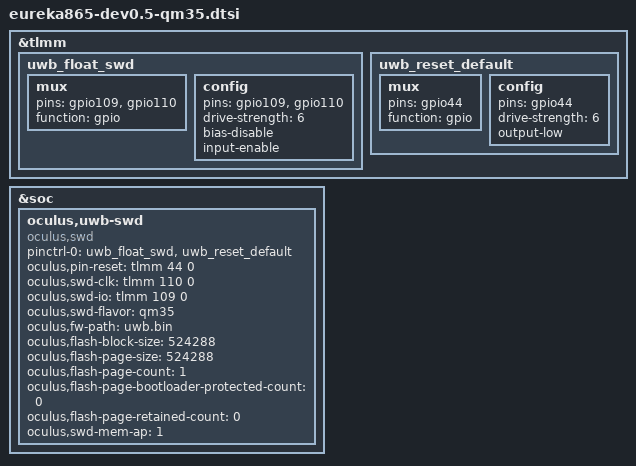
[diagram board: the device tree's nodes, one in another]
// SPDX-License-Identifier: GPL-2.0

&tlmm {
	uwb_float_swd: uwb_float_swd {
		mux {
			pins = "gpio109", "gpio110";
			function = "gpio";
		};

		config {
			pins = "gpio109", "gpio110";
			drive-strength = <6>;
			bias-disable;
			input-enable;
		};
	};

	uwb_reset_default: uwb_reset_default {
		mux {
			pins = "gpio44";
			function = "gpio";
		};

		config {
			pins = "gpio44";
			drive-strength = <6>;
			output-low;
		};
	};
};

&soc {
	oculus,uwb-swd {
		compatible = "oculus,swd";

		pinctrl-names = "default";
		pinctrl-0 = <&uwb_float_swd &uwb_reset_default>;

		oculus,pin-reset = <&tlmm 44 0>;
		oculus,swd-clk = <&tlmm 110 0>;
		oculus,swd-io = <&tlmm 109 0>;

		oculus,swd-flavor = "qm35";
		oculus,fw-path = "uwb.bin";
		/* 512 KiB of RRAM (not actual flash) */
		oculus,flash-block-size = <524288>;
		oculus,flash-page-size = <524288>;
		oculus,flash-page-count = <1>;
		oculus,flash-page-bootloader-protected-count = <0>;
		oculus,flash-page-retained-count = <0>;
		oculus,swd-mem-ap = <1>;
	};
};
